# HM1030 register map
File version: 0.1
Registers are 32-bit, read-write, reset 0x0 unless marked. A register's access mark holds for its fields unless they carry their own. Offsets are from the block's base; [hi:lo] are bit positions; lines under a group give offsets from that group; {n}, {i} and the like mark numbered series.

## SPI0 — Registers group
Base 0x400B8000
Same registers: SPI1 0x400B8800
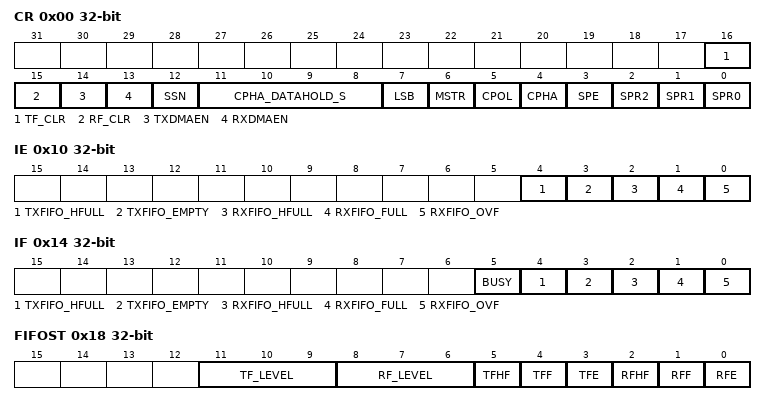
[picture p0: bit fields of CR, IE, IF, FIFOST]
0x00 CR
  [16] TF_CLR — 发送FIFO清除位
  [15] RF_CLR — 接收FIFO清除位
  [14] TXDMAEN — 发送DMA控制使能位
  [13] RXDMAEN — 接收DMA控制使能位
  [12] SSN — 主模式下SSN输出
  [11:8] CPHA_DATAHOLD_S — 从模式下 CPHA 为 1 时，数据保持时间配置寄存器
  [7] LSB — 数据传输顺序选择
  [6] MSTR — 主从模式选择
  [5] CPOL — 时钟极性选择
  [4] CPHA — 时钟相位选择
  [3] SPE — SPI系统使能
  [2] SPR2 — SPI波特率选择位2
  [1] SPR1 — SPI波特率选择位1
  [0] SPR0 — SPI波特率选择位0
0x04 WDR
  [7:0] WDR — 写数据寄存器
0x08 RDR
  [7:0] RDR ro — 读数据寄存器
0x10 IE
  [4] TXFIFO_HFULL — 发送FIFO半满中断使能
  [3] TXFIFO_EMPTY — 发送FIFO空中断使能
  [2] RXFIFO_HFULL — 接收FIFO半满中断使能
  [1] RXFIFO_FULL — 接收FIFO满中断使能
  [0] RXFIFO_OVF — 接收FIFO溢出中断使能
0x14 IF
  [5] BUSY — SPI忙标志
  [4] TXFIFO_HFULL — 发送FIFO半满标志
  [3] TXFIFO_EMPTY — 发送FIFO空标志
  [2] RXFIFO_HFULL — 接收FIFO半满标志
  [1] RXFIFO_FULL — 接收FIFO满标志
  [0] RXFIFO_OVF — 接收FIFO溢出标志
0x18 FIFOST
  [11:9] TF_LEVEL ro — 发送FIFO水位状态
  [8:6] RF_LEVEL ro — 接收FIFO水位状态
  [5] TFHF ro — 发送FIFO半满标志
  [4] TFF ro — 发送FIFO满标志
  [3] TFE ro — 发送FIFO空标志
  [2] RFHF ro — 接收FIFO半满标志
  [1] RFF ro — 接收FIFO满标志
  [0] RFE ro — 接收FIFO空标志

## IIC0 — Registers group
Base 0x400B9000
Same registers: IIC1 0x400B9800
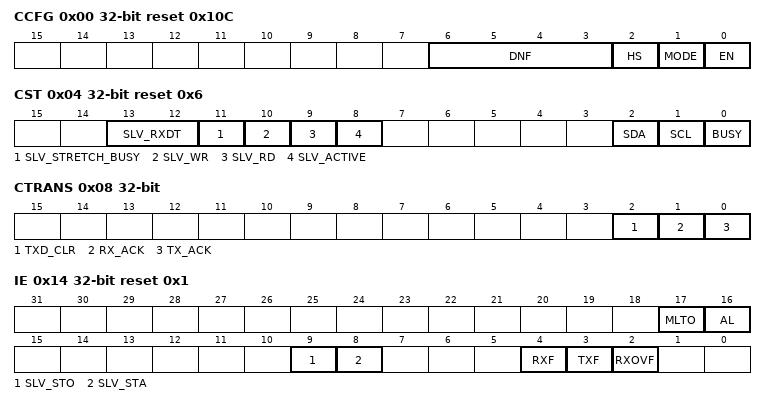
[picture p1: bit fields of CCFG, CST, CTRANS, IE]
0x00 CCFG reset 0x10C — 通用配置寄存器
  [6:3] DNF — ReceiveSDA、SCL数字噪声滤波
  [2] HS — High-speed mode。
  [1] MODE — 模式控制
  [0] EN — IIC 总线使能
0x04 CST ro reset 0x6
  [13:12] SLV_RXDT — Slave接收到的数据类型
  [11] SLV_STRETCH_BUSY — SlaveClockStretching忙状态
  [10] SLV_WR — Slave写状态
  [9] SLV_RD — Slave读状态
  [8] SLV_ACTIVE — Slave活跃状态
  [2] SDA — IICSDA状态
  [1] SCL — IICSCL状态
  [0] BUSY — 总线忙状态
0x08 CTRANS
  [2] TXD_CLR write — 发送数据寄存器清空
  [1] RX_ACK ro — 接收到的ACK/NACK
  [0] TX_ACK — 发送 ACK/NACK
0x0C RXDATA ro
  [7:0] RXDATA — 接收数据寄存器
0x10 TXDATA
  [7:0] TXDATA — 发送数据寄存器
0x14 IE reset 0x1
  [17] MLTO — Master SCL LOW 超时中断使能
  [16] AL — Master仲裁丢失总线中断使能
  [9] SLV_STO — Slave检测到STOP中断使能
  [8] SLV_STA — Slave检测到START中断使能
  [4] RXF — 接收数据结束中断使能
  [3] TXF — 发送数据结束中断使能
  [2] RXOVF — 接收数据寄存器溢出中断使能
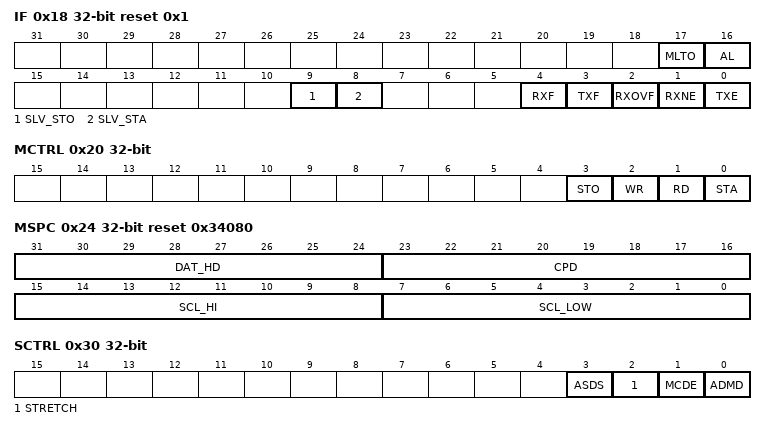
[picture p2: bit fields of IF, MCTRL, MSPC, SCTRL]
0x18 IF reset 0x1
  [17] MLTO — Master SCL LOW 超时
  [16] AL — Master仲裁丢失总线
  [9] SLV_STO — Slave检测到STOP
  [8] SLV_STA — Slave检测到START
  [4] RXF — 接收数据结束
  [3] TXF — 发送数据结束
  [2] RXOVF — 接收数据寄存器溢出
  [1] RXNE — 接收数据寄存器非空
  [0] TXE — 发送数据寄存器空
0x20 MCTRL
  [3] STO — 写1,产生STOP，
  [2] WR — 写1，发送TXDATA中数据
  [1] RD — 写1，接收数据到RXDATA中
  [0] STA — 写1，产生START
0x24 MSPC reset 0x34080
  [31:24] DAT_HD — SDA数据保持时间配置
  [23:16] CPD — 时钟预分频，详见SCL_HI和SCL_LOW描述
  [15:8] SCL_HI — SCL时钟高电平时间配置
  [7:0] SCL_LOW — SCL时钟低电平时间配置
0x30 SCTRL
  [3] ASDS — Stretching 后数据建立时间自适应使能
  [2] STRETCH — Clock stretching使能控制
  [1] MCDE — Master Code Detect Enable
  [0] ADMD — slave地址模式控制
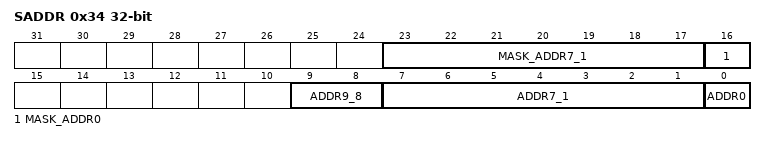
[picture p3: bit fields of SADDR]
0x34 SADDR
  [23:17] MASK_ADDR7_1 — Slave 对应地址位掩码
  [16] MASK_ADDR0 — Slave 对应地址位掩码
  [9:8] ADDR9_8 — 地址[9:8]
  [7:1] ADDR7_1 — 地址[7:1]
  [0] ADDR0 — 地址

## ADC — Registers group
Base 0x400BA000
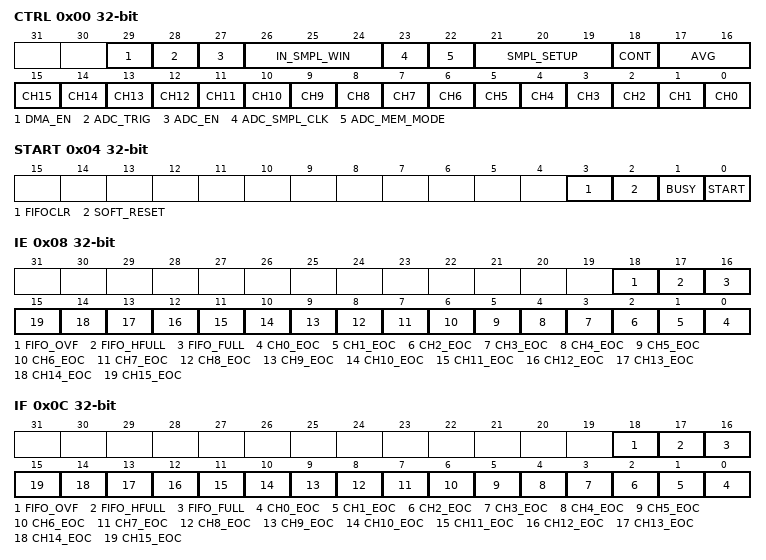
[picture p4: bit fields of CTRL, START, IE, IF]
0x00 CTRL
  [29] DMA_EN — DMA读取FIFO使能
  [28] ADC_TRIG — ADC触发源选择
  [27] ADC_EN — ADC使能位
  [26:24] IN_SMPL_WIN — ADC 内部采样时钟方式采样窗口设置
  [23] ADC_SMPL_CLK — ADC采样模式选择
  [22] ADC_MEM_MODE — ADC 数据存储方式选择
  [21:19] SMPL_SETUP — 外部采样时钟下采样建立时间
  [18] CONT — ADC 采样工作模式
  [17:16] AVG — 一次启动 ADC 采样取平均次数配置寄存器
  [n] CH{n} (n=0..15) — 通道{n}选中
0x04 START
  [3] FIFOCLR — FIFO清除使能
  [2] SOFT_RESET — 软复位使能
  [1] BUSY ro — 忙信号
  [0] START — 启动信号
0x08 IE
  [18] FIFO_OVF — FIFO溢出中断使能
  [17] FIFO_HFULL — FIFO半满中断使能
  [16] FIFO_FULL — FIFO满中断使能
  [n] CH{n}_EOC (n=0..15) — 通道{n}转换完成中断使能
0x0C IF
  [18] FIFO_OVF — FIFO溢出中断状态
  [17] FIFO_HFULL — FIFO半满中断状态
  [16] FIFO_FULL — FIFO满中断状态
  [n] CH{n}_EOC (n=0..15) — 通道{n}转换完成中断状态
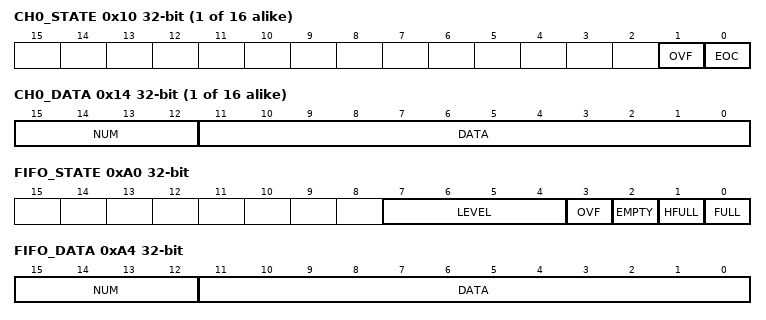
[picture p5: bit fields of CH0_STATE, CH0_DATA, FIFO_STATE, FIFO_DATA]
{0x10+8i} CH{i}_STATE ro (i=0..15)
  [1] OVF — 溢出标志
  [0] EOC — 转换完成标志
{0x14+8i} CH{i}_DATA ro (i=0..15)
  [15:12] NUM — 通道编号
  [11:0] DATA — 通道12bit数据
0xA0 FIFO_STATE ro
  [7:4] LEVEL rw — 水位
  [3] OVF rw — 溢出标志
  [2] EMPTY rw — 空标志
  [1] HFULL rw — 半满标志
  [0] FULL — 满标志
0xA4 FIFO_DATA ro
  [15:12] NUM — 通道编号
  [11:0] DATA — 通道12bit数据
0xB0 EXTTRIG_SEL — 外部信号触发ADC选择寄存器
  [11:0] DATA — 通道12bit数据
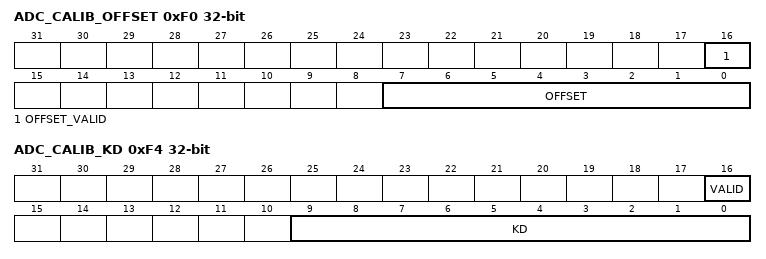
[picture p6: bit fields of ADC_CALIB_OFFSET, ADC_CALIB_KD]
0xF0 ADC_CALIB_OFFSET
  [16] OFFSET_VALID — OFFSET数据是否有效
  [7:0] OFFSET — ADC数据校准的OFFSET值
0xF4 ADC_CALIB_KD
  [16] VALID — KD数据是否有效
  [9:0] KD — ADC数据校准K值的小数部分

## AES — Registers group
Base 0x400BD000
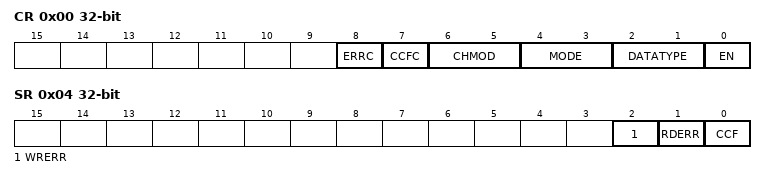
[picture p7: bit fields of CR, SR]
0x00 CR — 控制寄存器
  [8] ERRC — 错误标志清除
  [7] CCFC — 计算完成标志清除
  [6:5] CHMOD — 链接模式选择
  [4:3] MODE — 模式选择
  [2:1] DATATYPE — 数据类型选择
  [0] EN — 使能信号
0x04 SR ro — 状态寄存器
  [2] WRERR — 写入错误标志
  [1] RDERR — 读取错误标志
  [0] CCF — 计算完成标志
0x08 DINR — 输入数据寄存器
0x0C DOUTR ro — 输出数据寄存器
  [31:0] DOUTR — 数据输出寄存器
{0x10+4i} KEYR{i} (i=0..3) — 密钥寄存器{i}
  [31:0] KEYR — 密钥寄存器[{32i+31}:{32i}]
0x20 IVR0 — 加密起始点寄存器0
  [0] IVR — 初始化向量寄存器[31：0]
0x24 IVR1 — 加密起始点寄存器1
  [0] IVR — 初始化向量寄存器[63:32]
0x28 IVR2 — 加密起始点寄存器2
  [0] IVR — 初始化向量寄存器[95:64]
0x2C IVR3 — 加密起始点寄存器3
  [0] IVR — 初始化向量寄存器（MSB IVR [127：96]）
